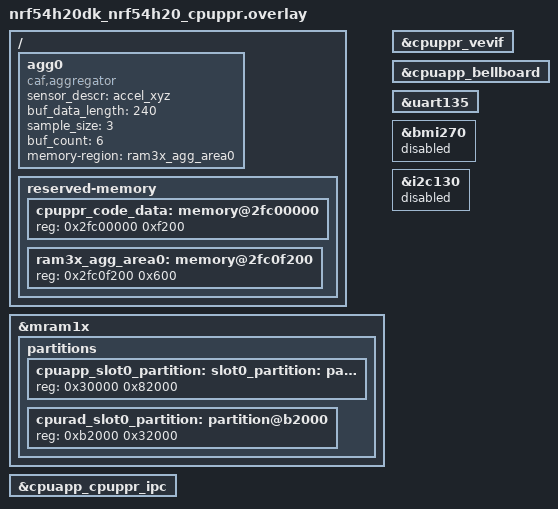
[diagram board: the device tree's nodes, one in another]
/*
 * Copyright (c) 2024 Nordic Semiconductor ASA
 *
 * SPDX-License-Identifier: LicenseRef-Nordic-5-Clause
 */

/ {
	agg0: agg0 {
		compatible = "caf,aggregator";
		sensor_descr = "accel_xyz";
		buf_data_length = <240>;
		sample_size = <3>;
		buf_count = <6>;
		memory-region = <&ram3x_agg_area0>;
		status = "okay";
	};

	reserved-memory {
		cpuppr_code_data: memory@2fc00000 {
			reg = <0x2fc00000 0xf200>;
		};

		ram3x_agg_area0: memory@2fc0f200 {
			reg = <0x2fc0f200 0x600>;
		};
	};
};

/delete-node/ &cpuapp_slot0_partition;
/delete-node/ &cpurad_slot0_partition;

/* This duplicates the Application core configuration to build PPR image under valid address. */
&mram1x {
	partitions {
		cpuapp_slot0_partition: slot0_partition: partition@30000 {
			reg = <0x30000 0x82000>;
		};

		cpurad_slot0_partition: partition@b2000 {
			reg = <0xb2000 0x32000>;
		};
	};
};

ipc1: &cpuapp_cpuppr_ipc {
	status = "okay";
};

&cpuppr_vevif {
	status = "okay";
};

&cpuapp_bellboard {
	status = "okay";
};

&uart135 {
	/delete-property/ hw-flow-control;
};

/* Disable unused sensors and peripherals. */
/delete-node/ &bme688;

&bmi270 {
	status = "disabled";
};

&i2c130 {
	status = "disabled";
};
